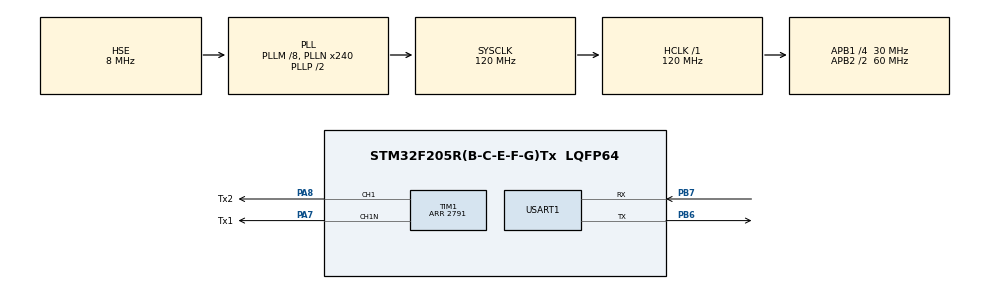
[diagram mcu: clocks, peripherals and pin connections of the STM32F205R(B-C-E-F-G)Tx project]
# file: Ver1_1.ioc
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Mcu.Family=STM32F2
Mcu.Name=STM32F205R(B-C-E-F-G)Tx
Mcu.Package=LQFP64
NVIC.PriorityGroup=NVIC_PRIORITYGROUP_4
NVIC.RCC_IRQn=true\:4\:0\:true\:true\:true\:4\:true
NVIC.TIM1_CC_IRQn=true\:1\:0\:true\:true\:true\:2\:true
NVIC.TIM1_UP_TIM10_IRQn=true\:3\:0\:true\:true\:true\:3\:true
NVIC.USART1_IRQn=true\:2\:0\:true\:true\:true\:1\:true
PA13.Mode=Serial_Wire
PA13.Signal=SYS_JTMS-SWDIO
PA14.Mode=Serial_Wire
PA14.Signal=SYS_JTCK-SWCLK
PA7.GPIO_Label=Tx1
PA7.GPIO_Speed=GPIO_SPEED_FREQ_VERY_HIGH
PA7.Mode=PWM Generation1 CH1 CH1N
PA7.Signal=TIM1_CH1N
PA8.GPIO_Label=Tx2
PA8.GPIO_Speed=GPIO_SPEED_FREQ_VERY_HIGH
PA8.Signal=S_TIM1_CH1
PB6.GPIO_Speed=GPIO_SPEED_FREQ_LOW
PB6.Mode=Asynchronous
PB6.Signal=USART1_TX
PB7.GPIO_Speed=GPIO_SPEED_FREQ_LOW
PB7.Mode=Asynchronous
PB7.Signal=USART1_RX
PH0-OSC_IN.Mode=HSE-External-Oscillator
PH0-OSC_IN.Signal=RCC_OSC_IN
PH1-OSC_OUT.Mode=HSE-External-Oscillator
PH1-OSC_OUT.Signal=RCC_OSC_OUT
ProjectManager.HeapSize=0x200
ProjectManager.StackSize=0x400
ProjectManager.TargetToolchain=EWARM
RCC.48MHZClocksFreq_Value=48000000
RCC.AHBFreq_Value=120000000
RCC.APB1CLKDivider=RCC_HCLK_DIV4
RCC.APB1Freq_Value=30000000
RCC.APB1TimFreq_Value=60000000
RCC.APB2CLKDivider=RCC_HCLK_DIV2
RCC.APB2Freq_Value=60000000
RCC.APB2TimFreq_Value=120000000
RCC.CortexFreq_Value=120000000
RCC.HCLKFreq_Value=120000000
RCC.HSE_VALUE=8000000
RCC.HSI_VALUE=16000000
RCC.LSE_VALUE=32768
RCC.PLLM=8
RCC.PLLN=240
RCC.PLLQ=5
RCC.PLLSourceVirtual=RCC_PLLSOURCE_HSE
RCC.SYSCLKFreq_VALUE=120000000
RCC.SYSCLKSource=RCC_SYSCLKSOURCE_PLLCLK
RCC.VCOOutputFreq_Value=240000000
SH.S_TIM1_CH1.0=TIM1_CH1,PWM Generation1 CH1 CH1N
TIM1.AutoReloadPreload=TIM_AUTORELOAD_PRELOAD_ENABLE
TIM1.AutomaticOutput=TIM_AUTOMATICOUTPUT_DISABLE
TIM1.BreakState=TIM_BREAK_DISABLE
TIM1.Channel-PWM\ Generation1\ CH1\ CH1N=TIM_CHANNEL_1
TIM1.DeadTime=0xc5
TIM1.OCFastMode_PWM-PWM\ Generation1\ CH1\ CH1N=TIM_OCFAST_ENABLE
TIM1.OCNIdleState_1=TIM_OCNIDLESTATE_SET
TIM1.OCNPolarity_1=TIM_OCNPOLARITY_LOW
TIM1.OffStateIDLEMode=TIM_OSSI_DISABLE
TIM1.OffStateRunMode=TIM_OSSR_DISABLE
TIM1.Period=2791
TIM1.Pulse-PWM\ Generation1\ CH1\ CH1N=1083
TIM1.RepetitionCounter=100
USART1.VirtualMode=VM_ASYNC
VP_RNG_VS_RNG.Mode=RNG_Activate
VP_WWDG_VS_WWDG.Mode=WWDG_Activate
board=Ver1_1

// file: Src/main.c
/**
  ******************************************************************************
  * @file           : main.c
  * @brief          : Main program body
  ******************************************************************************
  ** This notice applies to any and all portions of this file
  * that are not between comment pairs USER CODE BEGIN and
  * USER CODE END. Other portions of this file, whether
  * inserted by the user or by software development tools
  * are owned by their respective copyright owners.
  *
  * COPYRIGHT(c) 2018 STMicroelectronics
  *
  * Redistribution and use in source and binary forms, with or without modification,
  * are permitted provided that the following conditions are met:
  *   1. Redistributions of source code must retain the above copyright notice,
  *      this list of conditions and the following disclaimer.
  *   2. Redistributions in binary form must reproduce the above copyright notice,
  *      this list of conditions and the following disclaimer in the documentation
  *      and/or other materials provided with the distribution.
  *   3. Neither the name of STMicroelectronics nor the names of its contributors
  *      may be used to endorse or promote products derived from this software
  *      without specific prior written permission.
  *
  * THIS SOFTWARE IS PROVIDED BY THE COPYRIGHT HOLDERS AND CONTRIBUTORS "AS IS"
  * AND ANY EXPRESS OR IMPLIED WARRANTIES, INCLUDING, BUT NOT LIMITED TO, THE
  * IMPLIED WARRANTIES OF MERCHANTABILITY AND FITNESS FOR A PARTICULAR PURPOSE ARE
  * DISCLAIMED. IN NO EVENT SHALL THE COPYRIGHT HOLDER OR CONTRIBUTORS BE LIABLE
  * FOR ANY DIRECT, INDIRECT, INCIDENTAL, SPECIAL, EXEMPLARY, OR CONSEQUENTIAL
  * DAMAGES (INCLUDING, BUT NOT LIMITED TO, PROCUREMENT OF SUBSTITUTE GOODS OR
  * SERVICES; LOSS OF USE, DATA, OR PROFITS; OR BUSINESS INTERRUPTION) HOWEVER
  * CAUSED AND ON ANY THEORY OF LIABILITY, WHETHER IN CONTRACT, STRICT LIABILITY,
  * OR TORT (INCLUDING NEGLIGENCE OR OTHERWISE) ARISING IN ANY WAY OUT OF THE USE
  * OF THIS SOFTWARE, EVEN IF ADVISED OF THE POSSIBILITY OF SUCH DAMAGE.
  *
  ******************************************************************************
  */
#include "main.h"
#include "stm32f2xx_hal.h"

RNG_HandleTypeDef hrng;

TIM_HandleTypeDef htim1;

UART_HandleTypeDef huart1;

WWDG_HandleTypeDef hwwdg;

/* USER CODE BEGIN PV */
/* Private variables ---------------------------------------------------------*/

/* USER CODE END PV */

void SystemClock_Config(void);
static void MX_GPIO_Init(void);
static void MX_USART1_UART_Init(void);
static void MX_TIM1_Init(void);
static void MX_RNG_Init(void);
static void MX_WWDG_Init(void);
static void MX_NVIC_Init(void);

void HAL_TIM_MspPostInit(TIM_HandleTypeDef *htim);

/* USER CODE BEGIN PFP */
/* Private function prototypes -----------------------------------------------*/

/* USER CODE END PFP */

int main(void)
{

  /* MCU Configuration----------------------------------------------------------*/

  /* Reset of all peripherals, Initializes the Flash interface and the Systick. */
  HAL_Init();

  /* Configure the system clock */
  SystemClock_Config();

  /* Initialize all configured peripherals */
  MX_GPIO_Init();
  MX_USART1_UART_Init();
  MX_TIM1_Init();
  MX_RNG_Init();
  MX_WWDG_Init();

  /* Initialize interrupts */
  MX_NVIC_Init();
  /* USER CODE BEGIN 2 */

  /* Start channel 1 */
  if(HAL_TIM_PWM_Start(&htim1, TIM_CHANNEL_1) != HAL_OK)
  {
    /* Starting Error */
    Error_Handler();
  }
  /* Start channel 1N */
  if(HAL_TIMEx_PWMN_Start(&htim1, TIM_CHANNEL_1) != HAL_OK)
  {
    /* Starting Error */
    Error_Handler();
  }

  /* USER CODE END 2 */

  /* Infinite loop */
  while (1)
  {

  }

}

void SystemClock_Config(void)
{

  RCC_OscInitTypeDef RCC_OscInitStruct;
  RCC_ClkInitTypeDef RCC_ClkInitStruct;

    /**Initializes the CPU, AHB and APB busses clocks
    */
  RCC_OscInitStruct.OscillatorType = RCC_OSCILLATORTYPE_HSE;
  RCC_OscInitStruct.HSEState = RCC_HSE_ON;
  RCC_OscInitStruct.PLL.PLLState = RCC_PLL_ON;
  RCC_OscInitStruct.PLL.PLLSource = RCC_PLLSOURCE_HSE;
  RCC_OscInitStruct.PLL.PLLM = 8;
  RCC_OscInitStruct.PLL.PLLN = 240;
  RCC_OscInitStruct.PLL.PLLP = RCC_PLLP_DIV2;
  RCC_OscInitStruct.PLL.PLLQ = 5;
  if (HAL_RCC_OscConfig(&RCC_OscInitStruct) != HAL_OK)
  {
    _Error_Handler(__FILE__, __LINE__);
  }

    /**Initializes the CPU, AHB and APB busses clocks
    */
  RCC_ClkInitStruct.ClockType = RCC_CLOCKTYPE_HCLK|RCC_CLOCKTYPE_SYSCLK
                              |RCC_CLOCKTYPE_PCLK1|RCC_CLOCKTYPE_PCLK2;
  RCC_ClkInitStruct.SYSCLKSource = RCC_SYSCLKSOURCE_PLLCLK;
  RCC_ClkInitStruct.AHBCLKDivider = RCC_SYSCLK_DIV1;
  RCC_ClkInitStruct.APB1CLKDivider = RCC_HCLK_DIV4;
  RCC_ClkInitStruct.APB2CLKDivider = RCC_HCLK_DIV2;

  if (HAL_RCC_ClockConfig(&RCC_ClkInitStruct, FLASH_LATENCY_3) != HAL_OK)
  {
    _Error_Handler(__FILE__, __LINE__);
  }

    /**Configure the Systick interrupt time
    */
  HAL_SYSTICK_Config(HAL_RCC_GetHCLKFreq()/1000);

    /**Configure the Systick
    */
  HAL_SYSTICK_CLKSourceConfig(SYSTICK_CLKSOURCE_HCLK);

  /* SysTick_IRQn interrupt configuration */
  HAL_NVIC_SetPriority(SysTick_IRQn, 0, 0);
}

/**
  * @brief NVIC Configuration.
  * @retval None
  */
static void MX_NVIC_Init(void)
{
  /* USART1_IRQn interrupt configuration */
  HAL_NVIC_SetPriority(USART1_IRQn, 2, 0);
  HAL_NVIC_EnableIRQ(USART1_IRQn);
  /* TIM1_CC_IRQn interrupt configuration */
  HAL_NVIC_SetPriority(TIM1_CC_IRQn, 1, 0);
  HAL_NVIC_EnableIRQ(TIM1_CC_IRQn);
  /* TIM1_UP_TIM10_IRQn interrupt configuration */
  HAL_NVIC_SetPriority(TIM1_UP_TIM10_IRQn, 3, 0);
  HAL_NVIC_EnableIRQ(TIM1_UP_TIM10_IRQn);
  /* RCC_IRQn interrupt configuration */
  HAL_NVIC_SetPriority(RCC_IRQn, 4, 0);
  HAL_NVIC_EnableIRQ(RCC_IRQn);
}

/* RNG init function */
static void MX_RNG_Init(void)
{

  hrng.Instance = RNG;
  if (HAL_RNG_Init(&hrng) != HAL_OK)
  {
    _Error_Handler(__FILE__, __LINE__);
  }

}

/* TIM1 init function */
static void MX_TIM1_Init(void)
{

  TIM_MasterConfigTypeDef sMasterConfig;
  TIM_OC_InitTypeDef sConfigOC;
  TIM_BreakDeadTimeConfigTypeDef sBreakDeadTimeConfig;

  htim1.Instance = TIM1;
  htim1.Init.Prescaler = 0;
  htim1.Init.CounterMode = TIM_COUNTERMODE_UP;
  htim1.Init.Period = 2791;
  htim1.Init.ClockDivision = TIM_CLOCKDIVISION_DIV1;
  htim1.Init.RepetitionCounter = 100;
  htim1.Init.AutoReloadPreload = TIM_AUTORELOAD_PRELOAD_ENABLE;
  if (HAL_TIM_PWM_Init(&htim1) != HAL_OK)
  {
    _Error_Handler(__FILE__, __LINE__);
  }

  sMasterConfig.MasterOutputTrigger = TIM_TRGO_RESET;
  sMasterConfig.MasterSlaveMode = TIM_MASTERSLAVEMODE_DISABLE;
  if (HAL_TIMEx_MasterConfigSynchronization(&htim1, &sMasterConfig) != HAL_OK)
  {
    _Error_Handler(__FILE__, __LINE__);
  }

  sConfigOC.OCMode = TIM_OCMODE_PWM1;
  sConfigOC.Pulse = 1083;
  sConfigOC.OCPolarity = TIM_OCPOLARITY_HIGH;
  sConfigOC.OCNPolarity = TIM_OCNPOLARITY_LOW;
  sConfigOC.OCFastMode = TIM_OCFAST_ENABLE;
  sConfigOC.OCIdleState = TIM_OCIDLESTATE_RESET;
  sConfigOC.OCNIdleState = TIM_OCNIDLESTATE_SET;
  if (HAL_TIM_PWM_ConfigChannel(&htim1, &sConfigOC, TIM_CHANNEL_1) != HAL_OK)
  {
    _Error_Handler(__FILE__, __LINE__);
  }

  sBreakDeadTimeConfig.OffStateRunMode = TIM_OSSR_DISABLE;
  sBreakDeadTimeConfig.OffStateIDLEMode = TIM_OSSI_DISABLE;
  sBreakDeadTimeConfig.LockLevel = TIM_LOCKLEVEL_OFF;
  sBreakDeadTimeConfig.DeadTime = 0xc5;
  sBreakDeadTimeConfig.BreakState = TIM_BREAK_DISABLE;
  sBreakDeadTimeConfig.BreakPolarity = TIM_BREAKPOLARITY_HIGH;
  sBreakDeadTimeConfig.AutomaticOutput = TIM_AUTOMATICOUTPUT_DISABLE;
  if (HAL_TIMEx_ConfigBreakDeadTime(&htim1, &sBreakDeadTimeConfig) != HAL_OK)
  {
    _Error_Handler(__FILE__, __LINE__);
  }

  HAL_TIM_MspPostInit(&htim1);

}

/* USART1 init function */
static void MX_USART1_UART_Init(void)
{

  huart1.Instance = USART1;
  huart1.Init.BaudRate = 115200;
  huart1.Init.WordLength = UART_WORDLENGTH_8B;
  huart1.Init.StopBits = UART_STOPBITS_1;
  huart1.Init.Parity = UART_PARITY_NONE;
  huart1.Init.Mode = UART_MODE_TX_RX;
  huart1.Init.HwFlowCtl = UART_HWCONTROL_NONE;
  huart1.Init.OverSampling = UART_OVERSAMPLING_16;
  if (HAL_UART_Init(&huart1) != HAL_OK)
  {
    _Error_Handler(__FILE__, __LINE__);
  }

}

/* WWDG init function */
static void MX_WWDG_Init(void)
{

  hwwdg.Instance = WWDG;
  hwwdg.Init.Prescaler = WWDG_PRESCALER_1;
  hwwdg.Init.Window = 64;
  hwwdg.Init.Counter = 64;
  hwwdg.Init.EWIMode = WWDG_EWI_DISABLE;
  if (HAL_WWDG_Init(&hwwdg) != HAL_OK)
  {
    _Error_Handler(__FILE__, __LINE__);
  }

}

/** Configure pins as
        * Analog
        * Input
        * Output
        * EVENT_OUT
        * EXTI
*/
static void MX_GPIO_Init(void)
{

  /* GPIO Ports Clock Enable */
  __HAL_RCC_GPIOH_CLK_ENABLE();
  __HAL_RCC_GPIOA_CLK_ENABLE();
  __HAL_RCC_GPIOB_CLK_ENABLE();

}

void _Error_Handler(char *file, int line)
{
  while(1)
  {
  }
}

/************************ (C) COPYRIGHT STMicroelectronics *****END OF FILE****/
